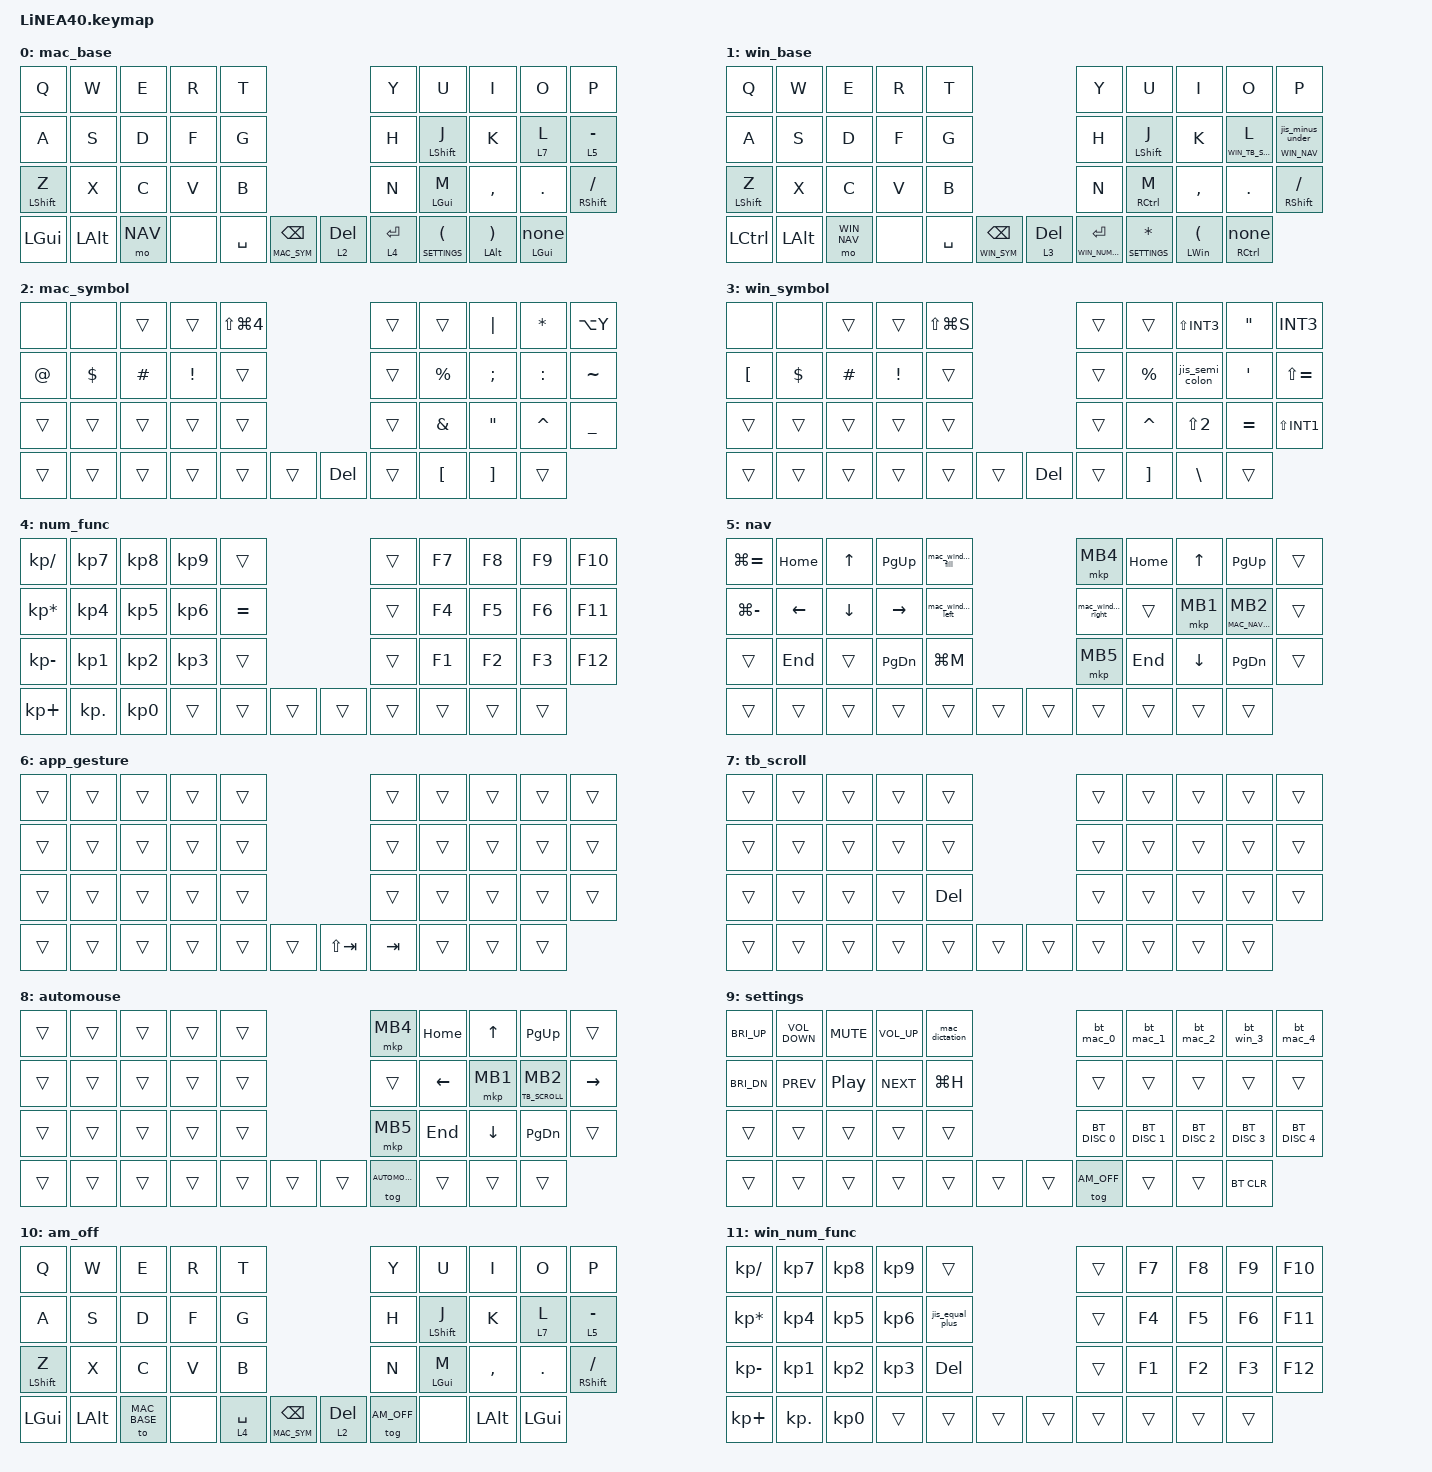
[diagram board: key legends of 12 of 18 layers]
#define ZMK_POINTING_DEFAULT_SCRL_VAL 9

#include <dt-bindings/zmk/input_transform.h>
#include <input/processors.dtsi>
#include <zephyr/dt-bindings/input/input-event-codes.h>
#include <behaviors.dtsi>
#include <dt-bindings/zmk/bt.h>
#include <dt-bindings/zmk/keys.h>
#include <dt-bindings/zmk/modifiers.h>
#include <dt-bindings/zmk/pointing.h>

#define MAC_BASE 0
#define WIN_BASE 1
#define MAC_SYM 2
#define WIN_SYM 3
#define NUM_FUNC 4
#define NAV 5
#define APP_GESTURE 6
#define TB_SCROLL 7
#define AUTOMOUSE 8
#define SETTINGS 9
#define AM_OFF 10
#define WIN_NUM_FUNC 11
#define WIN_NAV 12
#define WIN_RESTORE_PENDING 13
#define WIN_APP_GESTURE 14
#define NAV_HSCROLL 15
#define WIN_TB_SCROLL 16
#define MAC_NAV_HSCROLL 17

//mouse cursor

&mmv {
    delay-ms = <20>;
    trigger-period-ms = <5>;
    time-to-max-speed-ms = <100>;
    acceleration-exponent = <0>;
};

//mouse scroll

&msc {
    delay-ms = <0>;
    trigger-period-ms = <16>;
    time-to-max-speed-ms = <0>;
    acceleration-exponent = <0>;
};

&lt {
    flavor = "hold-preferred";
    tapping-term-ms = <200>;
    quick-tap-ms = <150>;
};

&mt {
    flavor = "tap-preferred";
    tapping-term-ms = <200>;
    quick-tap-ms = <150>;
    require-prior-idle-ms = <125>;
};

#define LEFT_HAND_KEYS  0 1 2 3 4 10 11 12 13 14 20 21 22 23 24 30 31 32 33 34 35
#define RIGHT_HAND_KEYS 5 6 7 8 9 15 16 17 18 19 25 26 27 28 29 36 37 38 39 40

/ {
    input_processors {
        zip_wheel_scaler: zip_wheel_scaler {
            compatible = "zmk,input-processor-scaler";
            #input-processor-cells = <2>;
            type = <INPUT_EV_REL>;
            codes = <INPUT_REL_WHEEL>;
            track-remainders;
        };

        tb_scroll_slow: tb_scroll_slow {
            compatible = "zmk,input-processor-scaler";
            #input-processor-cells = <2>;
            type = <INPUT_EV_REL>;
            codes = <INPUT_REL_WHEEL>;
            track-remainders;
        };

        mac_tb_scroll_slow: mac_tb_scroll_slow {
            compatible = "zmk,input-processor-scaler";
            #input-processor-cells = <2>;
            type = <INPUT_EV_REL>;
            codes = <INPUT_REL_WHEEL INPUT_REL_HWHEEL>;
            track-remainders;
        };

        tb_app_gestures: tb_app_gestures {
            compatible = "zmk,input-processor-directional-gestures";
            #input-processor-cells = <1>;
            type = <INPUT_EV_REL>;
            x-code = <INPUT_REL_X>;
            y-code = <INPUT_REL_Y>;
            cooldown-ms = <250>;
            bindings = <&gesture_mission_control>, <&gesture_app_expose>, <&gesture_space_right>, <&gesture_space_left>;
        };

        tb_win_app_gestures: tb_win_app_gestures {
            compatible = "zmk,input-processor-directional-gestures";
            #input-processor-cells = <1>;
            type = <INPUT_EV_REL>;
            x-code = <INPUT_REL_X>;
            y-code = <INPUT_REL_Y>;
            cooldown-ms = <250>;
            bindings = <&win_gesture_task_view>, <&win_gesture_show_desktop>, <&win_gesture_desktop_right>, <&win_gesture_desktop_left>;
        };
    };
};

&msc_input_listener {
    speed_up {
        layers = <NUM_FUNC WIN_NUM_FUNC>;
        input-processors = <&zip_wheel_scaler 3 1>;
    };
};

&trackball_listener {
    input-processors = <&zip_xy_scaler 0 1>;

    app_gestures {
        layers = <APP_GESTURE>;
        input-processors = <&tb_app_gestures 80>;
    };

    win_app_gestures {
        layers = <WIN_APP_GESTURE>;
        input-processors = <&tb_win_app_gestures 80>;
    };

    mac_scroller {
        layers = <TB_SCROLL MAC_NAV_HSCROLL>;
        input-processors =
            <&zip_xy_transform INPUT_TRANSFORM_Y_INVERT>,
            <&zip_xy_to_scroll_mapper>,
            <&mac_tb_scroll_slow 1 48>;
    };

    standard_scroller {
        layers = <WIN_TB_SCROLL NAV_HSCROLL>;
        input-processors =
            <&zip_xy_transform INPUT_TRANSFORM_Y_INVERT>,
            <&zip_xy_to_scroll_mapper>,
            <&tb_scroll_slow 3 16>;
    };

    cursor_movement {
        layers = <NAV WIN_NAV>;
    };
};

/ {
    combos {
        compatible = "zmk,combos";

        DeleteKey {
            bindings = <&kp DEL>;
            key-positions = <7 8>;
        };

        InsertKey {
            bindings = <&kp INS>;
            key-positions = <6 7>;
        };

        CenterClick {
            bindings = <&mkp MB3>;
            key-positions = <17 16>;
        };

        AppGestureLayer {
            bindings = <&app_switch_hold>;
            key-positions = <18 17>;
            layers = <MAC_BASE AUTOMOUSE AM_OFF APP_GESTURE>;
            timeout-ms = <50>;
        };

        WinAppGestureLayer {
            bindings = <&win_app_switch_hold>;
            key-positions = <18 17>;
            layers = <WIN_BASE WIN_APP_GESTURE>;
            timeout-ms = <50>;
        };

        PrevClick {
            bindings = <&mkp MB4>;
            key-positions = <27 28>;
        };

        ClickNext {
            bindings = <&mkp MB5>;
            key-positions = <26 27>;
        };

        EscapeBaseCombo {
            bindings = <&kp ESC>;
            key-positions = <0 1>;
            layers = <MAC_BASE WIN_BASE>;
            timeout-ms = <50>;
        };

        TabBaseCombo {
            bindings = <&kp TAB>;
            key-positions = <10 11>;
            layers = <MAC_BASE WIN_BASE>;
            timeout-ms = <50>;
        };

        ReturnBaseCombo {
            bindings = <&kp ENTER>;
            key-positions = <18 19>;
            layers = <MAC_BASE WIN_BASE>;
            timeout-ms = <50>;
        };

        MacThumbImeCombo {
            bindings = <&mac_ime_toggle>;
            key-positions = <34 37>;
            layers = <MAC_BASE AM_OFF>;
            timeout-ms = <50>;
        };

        WinThumbImeCombo {
            bindings = <&win_ime_toggle>;
            key-positions = <34 37>;
            layers = <WIN_BASE>;
            timeout-ms = <50>;
        };

        ThumbBackspaceRepeatCombo {
            bindings = <&kp BACKSPACE>;
            key-positions = <34 35>;
            layers = <MAC_BASE WIN_BASE AM_OFF>;
            timeout-ms = <50>;
        };

        ThumbDeleteRepeatCombo {
            bindings = <&kp DEL>;
            key-positions = <36 37>;
            layers = <MAC_BASE WIN_BASE AM_OFF>;
            timeout-ms = <50>;
        };

    };

    behaviors {
        re_kp: sensor_rotate_kp {
            compatible = "zmk,behavior-sensor-rotate-var";
            #sensor-binding-cells = <2>;
            bindings = <&kp>, <&kp>;
        };

        mouse_scrl: mouse_wheel_scrl {
            compatible = "zmk,behavior-sensor-rotate-accel";
            #sensor-binding-cells = <2>;
            bindings = <&msc>, <&msc>;
            tap-ms = <20>;
            detent-trigger-count = <2>;
            direction-confirm-ms = <300>;
            slow-interval-ms = <25>;
            fast-interval-ms = <25>;
            fast-trigger-count = <12>;
            slow-scale-percent = <12>;
            fast-scale-percent = <50>;
        };

        jis_minus_under: jis_minus_under {
            compatible = "zmk,behavior-mod-morph";
            #binding-cells = <0>;
            bindings = <&kp MINUS>, <&kp LS(INT1)>;
            mods = <(MOD_LSFT|MOD_RSFT)>;
        };

        jis_equal_plus: jis_equal_plus {
            compatible = "zmk,behavior-mod-morph";
            #binding-cells = <0>;
            bindings = <&kp LS(MINUS)>, <&kp LS(SEMICOLON)>;
            mods = <(MOD_LSFT|MOD_RSFT)>;
        };

        jis_semi_colon: jis_semi_colon {
            compatible = "zmk,behavior-mod-morph";
            #binding-cells = <0>;
            bindings = <&kp SEMICOLON>, <&kp APOS>;
            mods = <(MOD_LSFT|MOD_RSFT)>;
        };

        nav_minus_under: nav_minus_under {
            compatible = "zmk,behavior-hold-tap";
            #binding-cells = <2>;
            flavor = "hold-preferred";
            tapping-term-ms = <200>;
            quick-tap-ms = <150>;
            bindings = <&mo>, <&jis_minus_under>;
        };

        rclk_scroll: rclk_scroll {
            compatible = "zmk,behavior-hold-tap";
            #binding-cells = <2>;
            flavor = "hold-preferred";
            tapping-term-ms = <200>;
            quick-tap-ms = <150>;
            bindings = <&mo>, <&mkp>;
        };

        l_layer_tap: l_layer_tap {
            compatible = "zmk,behavior-hold-tap";
            #binding-cells = <2>;
            flavor = "balanced";
            tapping-term-ms = <220>;
            quick-tap-ms = <175>;
            require-prior-idle-ms = <125>;
            hold-trigger-key-positions = <LEFT_HAND_KEYS>;
            hold-trigger-on-release;
            bindings = <&mo>, <&kp>;
        };

        hm_left: homerow_mod_left {
            compatible = "zmk,behavior-hold-tap";
            #binding-cells = <2>;
            flavor = "balanced";
            tapping-term-ms = <250>;
            quick-tap-ms = <175>;
            require-prior-idle-ms = <125>;
            hold-trigger-key-positions = <RIGHT_HAND_KEYS>;
            hold-trigger-on-release;
            bindings = <&kp>, <&kp>;
        };

        hm_right: homerow_mod_right {
            compatible = "zmk,behavior-hold-tap";
            #binding-cells = <2>;
            flavor = "balanced";
            tapping-term-ms = <250>;
            quick-tap-ms = <175>;
            require-prior-idle-ms = <125>;
            hold-trigger-key-positions = <LEFT_HAND_KEYS>;
            hold-trigger-on-release;
            bindings = <&kp>, <&kp>;
        };

        bottom_mod_tap: bottom_mod_tap {
            compatible = "zmk,behavior-hold-tap";
            #binding-cells = <2>;
            flavor = "balanced";
            tapping-term-ms = <250>;
            quick-tap-ms = <175>;
            bindings = <&kp>, <&kp>;
        };

        bottom_mod_only: bottom_mod_only {
            compatible = "zmk,behavior-hold-tap";
            #binding-cells = <2>;
            flavor = "balanced";
            tapping-term-ms = <250>;
            quick-tap-ms = <175>;
            bindings = <&kp>, <&none>;
        };

        app_switch_hold: app_switch_hold {
            compatible = "zmk,behavior-macro";
            #binding-cells = <0>;
            wait-ms = <0>;
            tap-ms = <0>;
            bindings
                = <&macro_press &mo APP_GESTURE &kp LEFT_GUI>
                , <&macro_pause_for_release>
                , <&macro_release &kp LEFT_GUI &mo APP_GESTURE>;
        };

        win_app_switch_hold: win_app_switch_hold {
            compatible = "zmk,behavior-macro";
            #binding-cells = <0>;
            wait-ms = <0>;
            tap-ms = <0>;
            bindings
                = <&macro_press &mo WIN_APP_GESTURE &kp LEFT_ALT>
                , <&macro_pause_for_release>
                , <&macro_release &kp LEFT_ALT &mo WIN_APP_GESTURE>;
        };

        win_gesture_task_view: win_gesture_task_view {
            compatible = "zmk,behavior-macro";
            #binding-cells = <0>;
            wait-ms = <40>;
            tap-ms = <40>;
            bindings
                = <&macro_release &kp LEFT_ALT>
                , <&macro_tap &kp LG(TAB)>
                , <&macro_press &kp LEFT_ALT>;
        };

        win_gesture_show_desktop: win_gesture_show_desktop {
            compatible = "zmk,behavior-macro";
            #binding-cells = <0>;
            wait-ms = <40>;
            tap-ms = <40>;
            bindings
                = <&macro_release &kp LEFT_ALT>
                , <&macro_tap &kp LG(D)>
                , <&macro_press &kp LEFT_ALT>;
        };

        win_gesture_desktop_right: win_gesture_desktop_right {
            compatible = "zmk,behavior-macro";
            #binding-cells = <0>;
            wait-ms = <40>;
            tap-ms = <40>;
            bindings
                = <&macro_release &kp LEFT_ALT>
                , <&macro_tap &kp LC(LG(RIGHT_ARROW))>
                , <&macro_press &kp LEFT_ALT>;
        };

        win_gesture_desktop_left: win_gesture_desktop_left {
            compatible = "zmk,behavior-macro";
            #binding-cells = <0>;
            wait-ms = <40>;
            tap-ms = <40>;
            bindings
                = <&macro_release &kp LEFT_ALT>
                , <&macro_tap &kp LC(LG(LEFT_ARROW))>
                , <&macro_press &kp LEFT_ALT>;
        };

        gesture_mission_control: gesture_mission_control {
            compatible = "zmk,behavior-macro";
            #binding-cells = <0>;
            wait-ms = <10>;
            tap-ms = <20>;
            bindings
                = <&macro_release &kp LEFT_GUI>
                , <&macro_tap &kp LC(UP_ARROW)>
                , <&macro_press &kp LEFT_GUI>;
        };

        gesture_app_expose: gesture_app_expose {
            compatible = "zmk,behavior-macro";
            #binding-cells = <0>;
            wait-ms = <10>;
            tap-ms = <20>;
            bindings
                = <&macro_release &kp LEFT_GUI>
                , <&macro_tap &kp LC(DOWN_ARROW)>
                , <&macro_press &kp LEFT_GUI>;
        };

        gesture_space_right: gesture_space_right {
            compatible = "zmk,behavior-macro";
            #binding-cells = <0>;
            wait-ms = <10>;
            tap-ms = <20>;
            bindings
                = <&macro_release &kp LEFT_GUI>
                , <&macro_tap &kp LC(RIGHT_ARROW)>
                , <&macro_press &kp LEFT_GUI>;
        };

        gesture_space_left: gesture_space_left {
            compatible = "zmk,behavior-macro";
            #binding-cells = <0>;
            wait-ms = <10>;
            tap-ms = <20>;
            bindings
                = <&macro_release &kp LEFT_GUI>
                , <&macro_tap &kp LC(LEFT_ARROW)>
                , <&macro_press &kp LEFT_GUI>;
        };

        mac_window_left: mac_window_left {
            compatible = "zmk,behavior-macro";
            #binding-cells = <0>;
            wait-ms = <10>;
            tap-ms = <20>;
            bindings
                = <&macro_press &kp LEFT_GUI &kp LEFT_ALT>
                , <&macro_tap &kp LEFT_ARROW>
                , <&macro_release &kp LEFT_ALT &kp LEFT_GUI>;
        };

        mac_window_right: mac_window_right {
            compatible = "zmk,behavior-macro";
            #binding-cells = <0>;
            wait-ms = <10>;
            tap-ms = <20>;
            bindings
                = <&macro_press &kp LEFT_GUI &kp LEFT_ALT>
                , <&macro_tap &kp RIGHT_ARROW>
                , <&macro_release &kp LEFT_ALT &kp LEFT_GUI>;
        };

        mac_window_fill: mac_window_fill {
            compatible = "zmk,behavior-macro";
            #binding-cells = <0>;
            wait-ms = <10>;
            tap-ms = <20>;
            bindings
                = <&macro_press &kp LEFT_GUI &kp LEFT_ALT &kp LEFT_SHIFT>
                , <&macro_tap &kp F>
                , <&macro_release &kp LEFT_SHIFT &kp LEFT_ALT &kp LEFT_GUI>;
        };

        win_window_minimize: win_window_minimize {
            compatible = "zmk,behavior-macro";
            #binding-cells = <0>;
            wait-ms = <40>;
            tap-ms = <20>;
            bindings
                = <&macro_tap &kp LA(SPACE)>
                , <&macro_tap &kp N>
                , <&tog WIN_RESTORE_PENDING>;
        };

        win_window_maximize: win_window_maximize {
            compatible = "zmk,behavior-macro";
            #binding-cells = <0>;
            wait-ms = <40>;
            tap-ms = <20>;
            bindings
                = <&macro_tap &kp LA(SPACE)>
                , <&macro_tap &kp X>;
        };

        win_window_left_snap: win_window_left_snap {
            compatible = "zmk,behavior-macro";
            #binding-cells = <0>;
            wait-ms = <40>;
            tap-ms = <40>;
            bindings
                = <&macro_tap &kp LS(LG(DOWN_ARROW))>
                , <&macro_wait_time 150>
                , <&macro_tap &kp LG(LEFT_ARROW)>;
        };

        win_window_right_snap: win_window_right_snap {
            compatible = "zmk,behavior-macro";
            #binding-cells = <0>;
            wait-ms = <40>;
            tap-ms = <40>;
            bindings
                = <&macro_tap &kp LS(LG(DOWN_ARROW))>
                , <&macro_wait_time 150>
                , <&macro_tap &kp LG(RIGHT_ARROW)>;
        };

        win_window_restore_maximize: win_window_restore_maximize {
            compatible = "zmk,behavior-macro";
            #binding-cells = <0>;
            wait-ms = <40>;
            tap-ms = <40>;
            bindings
                = <&tog WIN_RESTORE_PENDING>
                , <&macro_press &kp LEFT_ALT>
                , <&macro_tap &kp TAB>
                , <&macro_wait_time 250>
                , <&macro_release &kp LEFT_ALT>
                , <&macro_wait_time 500>
                , <&macro_tap &kp LA(SPACE)>
                , <&macro_wait_time 100>
                , <&macro_tap &kp X>;
        };

        mac_dictation: mac_dictation {
            compatible = "zmk,behavior-macro";
            #binding-cells = <0>;
            wait-ms = <80>;
            tap-ms = <40>;
            bindings
                = <&macro_tap &kp GLOBE>
                , <&macro_tap &kp GLOBE>;
        };

        mac_ime_toggle: mac_ime_toggle {
            compatible = "zmk,behavior-macro";
            #binding-cells = <0>;
            wait-ms = <20>;
            tap-ms = <20>;
            bindings = <&kp LC(SPACE)>;
        };

        win_ime_toggle: win_ime_toggle {
            compatible = "zmk,behavior-macro";
            #binding-cells = <0>;
            wait-ms = <20>;
            tap-ms = <20>;
            bindings = <&kp GRAVE>;
        };

        delete_sym: delete_sym {
            compatible = "zmk,behavior-hold-tap";
            #binding-cells = <2>;
            flavor = "tap-preferred";
            tapping-term-ms = <300>;
            quick-tap-ms = <200>;
            bindings = <&mo>, <&kp>;
        };

        mac_ime_sym: mac_ime_sym {
            compatible = "zmk,behavior-hold-tap";
            #binding-cells = <2>;
            flavor = "tap-preferred";
            tapping-term-ms = <300>;
            quick-tap-ms = <200>;
            bindings = <&mo>, <&mac_ime_toggle>;
        };

        win_ime_sym: win_ime_sym {
            compatible = "zmk,behavior-hold-tap";
            #binding-cells = <2>;
            flavor = "tap-preferred";
            tapping-term-ms = <300>;
            quick-tap-ms = <200>;
            bindings = <&mo>, <&kp>;
        };

        bt_mac_0: bt_mac_0 {
            compatible = "zmk,behavior-macro";
            #binding-cells = <0>;
            bindings = <&to MAC_BASE>, <&bt BT_SEL 0>;
        };

        bt_mac_1: bt_mac_1 {
            compatible = "zmk,behavior-macro";
            #binding-cells = <0>;
            bindings = <&to MAC_BASE>, <&bt BT_SEL 1>;
        };

        bt_mac_2: bt_mac_2 {
            compatible = "zmk,behavior-macro";
            #binding-cells = <0>;
            bindings = <&to MAC_BASE>, <&bt BT_SEL 2>;
        };

        bt_win_3: bt_win_3 {
            compatible = "zmk,behavior-macro";
            #binding-cells = <0>;
            bindings = <&to WIN_BASE>, <&bt BT_SEL 3>;
        };

        bt_mac_4: bt_mac_4 {
            compatible = "zmk,behavior-macro";
            #binding-cells = <0>;
            bindings = <&to MAC_BASE>, <&bt BT_SEL 4>;
        };
    };

    keymap {
        compatible = "zmk,keymap";

        mac_base {
            bindings = <
&kp Q              &kp W         &kp E         &kp R      &kp T                                      &kp Y              &kp U           &kp I       &kp O      &kp P
&kp A              &kp S         &kp D         &kp F      &kp G                                      &kp H              &hm_right LEFT_SHIFT J &kp K       &l_layer_tap 7 L    &lt 5 MINUS
&hm_left LEFT_SHIFT Z   &kp X         &kp C         &kp V      &kp B                                      &kp N              &hm_right LEFT_GUI M   &kp COMMA   &kp DOT    &hm_right RIGHT_SHIFT SLASH
&kp LEFT_GUI  &kp LEFT_ALT  &mo NAV      &none      &kp SPACE  &delete_sym MAC_SYM BACKSPACE  &lt 2 DEL  &lt 4 ENTER  &lt SETTINGS LEFT_PARENTHESIS  &bottom_mod_tap LEFT_ALT RIGHT_PARENTHESIS  &bottom_mod_only LEFT_GUI 0
            >;

            sensor-bindings = <&mouse_scrl MOVE_UP MOVE_DOWN>;
        };

        win_base {
            bindings = <
&kp Q                &kp W         &kp E         &kp R      &kp T                                   &kp Y              &kp U             &kp I       &kp O      &kp P
&kp A                &kp S         &kp D         &kp F      &kp G                                   &kp H              &hm_right LEFT_SHIFT J   &kp K       &l_layer_tap WIN_TB_SCROLL L    &nav_minus_under WIN_NAV 0
&hm_left LEFT_SHIFT Z     &kp X         &kp C         &kp V      &kp B                                   &kp N              &hm_right RIGHT_CONTROL M &kp COMMA   &kp DOT    &hm_right RIGHT_SHIFT SLASH
&kp LEFT_CONTROL  &kp LEFT_ALT  &mo WIN_NAV      &none      &kp SPACE  &delete_sym WIN_SYM BACKSPACE  &lt 3 DEL  &lt WIN_NUM_FUNC ENTER  &lt SETTINGS ASTERISK  &bottom_mod_tap LEFT_WIN LEFT_PARENTHESIS  &bottom_mod_only RIGHT_CONTROL 0
            >;

            sensor-bindings = <&mouse_scrl MOVE_UP MOVE_DOWN>;
        };

        mac_symbol {
            bindings = <
&none        &none            &trans    &trans    &kp LS(LG(N4))                        &trans     &trans         &kp PIPE      &kp ASTERISK      &kp LA(Y)
&kp AT       &kp DOLLAR        &kp HASH  &kp EXCLAMATION &trans                                &trans     &kp PERCENT    &kp SEMICOLON &kp COLON             &kp TILDE
&trans       &trans            &trans    &trans     &trans                                &trans     &kp AMPERSAND  &kp DOUBLE_QUOTES &kp CARET         &kp UNDER
&trans       &trans            &trans    &trans    &trans        &trans    &kp DEL         &trans     &kp LBKT        &kp RIGHT_BRACKET &trans
            >;

            sensor-bindings = <&mouse_scrl MOVE_UP MOVE_DOWN>;
        };

        win_symbol {
            bindings = <
&none        &none            &trans    &trans    &kp LS(LG(S))                         &trans     &trans         &kp LS(INT3)        &kp DOUBLE_QUOTES &kp INT3
&kp LBKT     &kp DOLLAR       &kp HASH  &kp EXCLAMATION &trans                               &trans     &kp PERCENT    &jis_semi_colon &kp APOS          &kp LS(EQUAL)
&trans       &trans           &trans    &trans     &trans                               &trans     &kp CARET      &kp LS(N2)    &kp EQUAL         &kp LS(INT1)
&trans       &trans           &trans    &trans    &trans        &trans    &kp DEL        &trans     &kp RIGHT_BRACKET &kp BACKSLASH &trans
            >;

            sensor-bindings = <&mouse_scrl MOVE_UP MOVE_DOWN>;
        };

        num_func {
            bindings = <
&kp KP_SLASH     &kp KP_NUMBER_7  &kp KP_NUMBER_8  &kp KP_NUMBER_9  &trans                              &trans  &kp F7  &kp F8  &kp F9  &kp F10
&kp KP_MULTIPLY  &kp KP_NUMBER_4  &kp KP_NUMBER_5  &kp KP_NUMBER_6  &kp EQUAL                           &trans  &kp F4  &kp F5  &kp F6  &kp F11
&kp KP_MINUS     &kp KP_NUMBER_1  &kp KP_NUMBER_2  &kp KP_NUMBER_3  &trans                              &trans  &kp F1  &kp F2  &kp F3  &kp F12
&kp KP_PLUS      &kp KP_DOT       &kp KP_NUMBER_0  &trans           &trans       &trans    &trans        &trans  &trans  &trans  &trans
            >;

            sensor-bindings = <&mouse_scrl MOVE_UP MOVE_DOWN>;
        };

        nav {
            bindings = <
&kp LG(EQUAL)   &kp HOME  &kp UP_ARROW    &kp PAGE_UP    &mac_window_fill                         &mkp MB4     &kp HOME  &kp UP_ARROW  &kp PAGE_UP    &trans
&kp LG(MINUS)  &kp LEFT_ARROW  &kp DOWN_ARROW  &kp RIGHT_ARROW  &mac_window_left       &mac_window_right       &trans    &mkp MB1      &rclk_scroll MAC_NAV_HSCROLL MB2       &trans
&trans             &kp END   &trans          &kp PAGE_DOWN  &kp LG(M)                         &mkp MB5     &kp END   &kp DOWN_ARROW &kp PAGE_DOWN  &trans
&trans         &trans    &trans          &trans         &trans       &trans    &trans       &trans      &trans    &trans         &trans
            >;

            sensor-bindings = <&mouse_scrl MOVE_UP MOVE_DOWN>;
        };

        app_gesture {
            bindings = <
&trans  &trans  &trans  &trans  &trans                              &trans  &trans  &trans          &trans       &trans
&trans  &trans  &trans  &trans  &trans                              &trans  &trans  &trans          &trans       &trans
&trans  &trans  &trans  &trans  &trans                              &trans  &trans  &trans          &trans       &trans
&trans  &trans  &trans  &trans  &trans       &trans    &kp LS(TAB)  &kp TAB  &trans  &trans  &trans
            >;

            sensor-bindings = <&mouse_scrl MOVE_UP MOVE_DOWN>;
        };

        tb_scroll {
            bindings = <
&trans  &trans  &trans  &trans  &trans                              &trans  &trans  &trans  &trans  &trans
&trans  &trans  &trans  &trans  &trans                              &trans  &trans  &trans  &trans  &trans
&trans  &trans  &trans  &trans  &kp DEL                             &trans  &trans  &trans  &trans  &trans
&trans  &trans  &trans  &trans  &trans       &trans    &trans       &trans  &trans  &trans  &trans
            >;

            sensor-bindings = <&mouse_scrl MOVE_UP MOVE_DOWN>;
        };

        automouse {
            bindings = <
&trans  &trans  &trans  &trans  &trans                              &mkp MB4  &kp HOME  &kp UP_ARROW    &kp PAGE_UP    &trans
&trans  &trans  &trans  &trans  &trans                              &trans      &kp LEFT_ARROW  &mkp MB1        &rclk_scroll TB_SCROLL MB2   &kp RIGHT_ARROW
&trans  &trans  &trans  &trans  &trans                              &mkp MB5  &kp END   &kp DOWN_ARROW  &kp PAGE_DOWN  &trans
&trans  &trans  &trans  &trans  &trans       &trans    &trans       &tog AUTOMOUSE &trans    &trans          &trans
            >;

            sensor-bindings = <&mouse_scrl MOVE_UP MOVE_DOWN>;
        };

        settings {
            bindings = <
&kp C_BRI_UP  &kp C_VOLUME_DOWN  &kp C_MUTE  &kp C_VOLUME_UP  &mac_dictation                      &bt_mac_0  &bt_mac_1   &bt_mac_2  &bt_win_3   &bt_mac_4
&kp C_BRI_DN  &kp C_PREV         &kp C_PP    &kp C_NEXT       &kp LG(H)                          &trans     &trans      &trans     &trans      &trans
&trans        &trans             &trans      &trans           &trans                             &bt BT_DISC 0  &bt BT_DISC 1  &bt BT_DISC 2  &bt BT_DISC 3  &bt BT_DISC 4
&trans        &trans             &trans      &trans           &trans       &trans    &trans       &tog AM_OFF  &trans     &trans      &bt BT_CLR
            >;

            sensor-bindings = <&mouse_scrl MOVE_UP MOVE_DOWN>;
        };

        am_off {
            bindings = <
&kp Q              &kp W         &kp E         &kp R      &kp T                                      &kp Y              &kp U           &kp I       &kp O      &kp P
&kp A              &kp S         &kp D         &kp F      &kp G                                      &kp H              &hm_right LEFT_SHIFT J &kp K       &l_layer_tap 7 L    &lt 5 MINUS
&hm_left LEFT_SHIFT Z   &kp X         &kp C         &kp V      &kp B                                      &kp N              &hm_right LEFT_GUI M   &kp COMMA   &kp DOT    &hm_right RIGHT_SHIFT SLASH
&kp LEFT_GUI       &kp LEFT_ALT  &to MAC_BASE  &none      &lt 4 SPACE  &delete_sym MAC_SYM BACKSPACE  &lt 2 DEL  &tog AM_OFF  &none  &kp LEFT_ALT  &kp LEFT_GUI
            >;

            sensor-bindings = <&mouse_scrl MOVE_UP MOVE_DOWN>;
        };

        win_num_func {
            bindings = <
&kp KP_SLASH     &kp KP_NUMBER_7  &kp KP_NUMBER_8  &kp KP_NUMBER_9  &trans                              &trans  &kp F7  &kp F8  &kp F9  &kp F10
&kp KP_MULTIPLY  &kp KP_NUMBER_4  &kp KP_NUMBER_5  &kp KP_NUMBER_6  &jis_equal_plus                      &trans  &kp F4  &kp F5  &kp F6  &kp F11
&kp KP_MINUS     &kp KP_NUMBER_1  &kp KP_NUMBER_2  &kp KP_NUMBER_3  &kp DEL                             &trans  &kp F1  &kp F2  &kp F3  &kp F12
&kp KP_PLUS      &kp KP_DOT       &kp KP_NUMBER_0  &trans           &trans       &trans    &trans        &trans  &trans  &trans  &trans
            >;

            sensor-bindings = <&mouse_scrl MOVE_UP MOVE_DOWN>;
        };

        win_nav {
            bindings = <
&kp LC(KP_PLUS)   &kp HOME        &kp UP_ARROW    &kp PAGE_UP     &win_window_maximize        &mkp MB4  &kp HOME  &kp UP_ARROW    &kp PAGE_UP    &trans
&kp LC(KP_MINUS)  &kp LEFT_ARROW  &kp DOWN_ARROW  &kp RIGHT_ARROW &win_window_left_snap     &win_window_right_snap    &trans    &mkp MB1        &rclk_scroll NAV_HSCROLL MB2       &trans
&trans            &kp END         &trans          &kp PAGE_DOWN   &win_window_minimize                   &mkp MB5  &kp END   &kp DOWN_ARROW  &kp PAGE_DOWN  &trans
&trans            &trans         &trans          &trans          &trans      &trans    &trans    &trans        &trans        &trans       &trans
            >;

            sensor-bindings = <&mouse_scrl MOVE_UP MOVE_DOWN>;
        };

        win_restore_pending {
            bindings = <
&trans  &trans  &trans  &trans  &win_window_restore_maximize       &trans  &trans  &trans  &trans  &trans
&trans  &trans  &trans  &trans  &trans                              &trans  &trans  &trans  &trans  &trans
&trans  &trans  &trans  &trans  &none                               &trans  &trans  &trans  &trans  &trans
&trans  &trans  &trans  &trans  &trans       &trans    &trans       &trans  &trans  &trans  &trans
            >;

            sensor-bindings = <&mouse_scrl MOVE_UP MOVE_DOWN>;
        };

        win_app_gesture {
            bindings = <
&trans  &trans  &trans  &trans  &trans                              &trans  &trans  &trans          &trans       &trans
&trans  &trans  &trans  &trans  &trans                              &trans  &trans  &trans          &trans       &trans
&trans  &trans  &trans  &trans  &trans                              &trans  &trans  &trans          &trans       &trans
&trans  &trans  &trans  &trans  &trans       &trans    &kp LS(TAB)  &kp TAB  &trans  &trans  &trans
            >;

            sensor-bindings = <&mouse_scrl MOVE_UP MOVE_DOWN>;
        };

        nav_hscroll {
            bindings = <
&trans  &trans  &trans  &trans  &trans                              &trans  &trans  &trans  &trans  &trans
&trans  &trans  &trans  &trans  &trans                              &trans  &trans  &trans  &trans  &trans
&trans  &trans  &trans  &trans  &trans                              &trans  &trans  &trans  &trans  &trans
&trans  &trans  &trans  &trans  &trans       &trans    &trans       &trans  &trans  &trans  &trans
            >;

            sensor-bindings = <&mouse_scrl MOVE_RIGHT MOVE_LEFT>;
        };

        win_tb_scroll {
            bindings = <
&trans  &trans  &trans  &trans  &trans                              &trans  &trans  &trans  &trans  &trans
&trans  &trans  &trans  &trans  &trans                              &trans  &trans  &trans  &trans  &trans
&trans  &trans  &trans  &trans  &kp DEL                             &trans  &trans  &trans  &trans  &trans
&trans  &trans  &trans  &trans  &trans       &trans    &trans       &trans  &trans  &trans  &trans
            >;

            sensor-bindings = <&mouse_scrl MOVE_UP MOVE_DOWN>;
        };

        mac_nav_hscroll {
            bindings = <
&trans  &trans  &trans  &trans  &trans                              &trans  &trans  &trans  &trans  &trans
&trans  &trans  &trans  &trans  &trans                              &trans  &trans  &trans  &trans  &trans
&trans  &trans  &trans  &trans  &trans                              &trans  &trans  &trans  &trans  &trans
&trans  &trans  &trans  &trans  &trans       &trans    &trans       &trans  &trans  &trans  &trans
            >;

            sensor-bindings = <&mouse_scrl MOVE_RIGHT MOVE_LEFT>;
        };
    };
};
